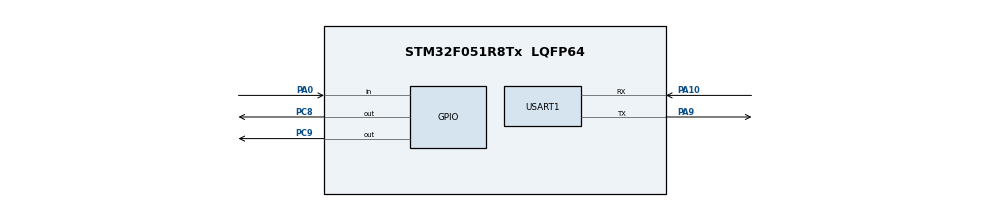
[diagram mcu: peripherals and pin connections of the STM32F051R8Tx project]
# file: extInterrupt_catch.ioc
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Mcu.Family=STM32F0
Mcu.Name=STM32F051R8Tx
Mcu.Package=LQFP64
PA0.GPIO_PuPd=GPIO_PULLUP
PA0.Signal=GPIO_Input
PA10.Mode=Asynchronous
PA10.Signal=USART1_RX
PA9.Mode=Asynchronous
PA9.Signal=USART1_TX
PC8.Signal=GPIO_Output
PC9.Signal=GPIO_Output
ProjectManager.HeapSize=0x200
ProjectManager.StackSize=0x400
ProjectManager.TargetToolchain=MDK-ARM V5.27
RCC.AHBFreq_Value=8000000
RCC.APB1Freq_Value=8000000
RCC.APB1TimFreq_Value=8000000
RCC.HCLKFreq_Value=8000000
USART1.VirtualMode-Asynchronous=VM_ASYNC
board=custom

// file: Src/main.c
/* USER CODE BEGIN Header */
/**
  ******************************************************************************
  * @file           : main.c
  * @brief          : Main program body
  ******************************************************************************
  * @attention
  *
  * <h2><center>&copy; Copyright (c) 2020 STMicroelectronics.
  * All rights reserved.</center></h2>
  *
  * This software component is licensed by ST under BSD 3-Clause license,
  * the "License"; You may not use this file except in compliance with the
  * License. You may obtain a copy of the License at:
  *                        opensource.org/licenses/BSD-3-Clause
  *
  ******************************************************************************
  */
/* USER CODE END Header */

#include "main.h"

UART_HandleTypeDef huart1;

void SystemClock_Config(void);
static void MX_GPIO_Init(void);
static void MX_USART1_UART_Init(void);
static void MX_NVIC_Init(void);
/* USER CODE BEGIN PFP */

void HAL_GPIO_EXTI_Callback(uint16_t GPIO_Pin);
/* USER CODE END PFP */

int main(void)
{

  /* MCU Configuration--------------------------------------------------------*/

  /* Reset of all peripherals, Initializes the Flash interface and the Systick. */
  HAL_Init();

  /* Configure the system clock */
  SystemClock_Config();

  /* Initialize all configured peripherals */
  MX_GPIO_Init();
  MX_USART1_UART_Init();

  /* Initialize interrupts */
  MX_NVIC_Init();
  /* USER CODE BEGIN 2 */
  HAL_UART_Transmit(&huart1, "START\n", 6, 10);

  /* USER CODE END 2 */

  /* Infinite loop */
  while (1)
  {
	  if(HAL_GPIO_ReadPin(GPIOA, GPIO_PIN_0) == 1){
		  HAL_GPIO_WritePin(GPIOC, GPIO_PIN_9,GPIO_PIN_SET);
	  }
	  else{
		  HAL_GPIO_WritePin(GPIOC, GPIO_PIN_9,GPIO_PIN_RESET);
	  }

  }
}

void SystemClock_Config(void)
{
  RCC_OscInitTypeDef RCC_OscInitStruct = {0};
  RCC_ClkInitTypeDef RCC_ClkInitStruct = {0};
  RCC_PeriphCLKInitTypeDef PeriphClkInit = {0};

  /** Initializes the CPU, AHB and APB busses clocks
  */
  RCC_OscInitStruct.OscillatorType = RCC_OSCILLATORTYPE_HSI;
  RCC_OscInitStruct.HSIState = RCC_HSI_ON;
  RCC_OscInitStruct.HSICalibrationValue = RCC_HSICALIBRATION_DEFAULT;
  RCC_OscInitStruct.PLL.PLLState = RCC_PLL_NONE;
  if (HAL_RCC_OscConfig(&RCC_OscInitStruct) != HAL_OK)
  {
    Error_Handler();
  }
  /** Initializes the CPU, AHB and APB busses clocks
  */
  RCC_ClkInitStruct.ClockType = RCC_CLOCKTYPE_HCLK|RCC_CLOCKTYPE_SYSCLK
                              |RCC_CLOCKTYPE_PCLK1;
  RCC_ClkInitStruct.SYSCLKSource = RCC_SYSCLKSOURCE_HSI;
  RCC_ClkInitStruct.AHBCLKDivider = RCC_SYSCLK_DIV1;
  RCC_ClkInitStruct.APB1CLKDivider = RCC_HCLK_DIV1;

  if (HAL_RCC_ClockConfig(&RCC_ClkInitStruct, FLASH_LATENCY_0) != HAL_OK)
  {
    Error_Handler();
  }
  PeriphClkInit.PeriphClockSelection = RCC_PERIPHCLK_USART1;
  PeriphClkInit.Usart1ClockSelection = RCC_USART1CLKSOURCE_PCLK1;
  if (HAL_RCCEx_PeriphCLKConfig(&PeriphClkInit) != HAL_OK)
  {
    Error_Handler();
  }
}

/**
  * @brief NVIC Configuration.
  * @retval None
  */
static void MX_NVIC_Init(void)
{
  /* EXTI0_1_IRQn interrupt configuration */
  HAL_NVIC_SetPriority(EXTI0_1_IRQn, 2, 0);
  HAL_NVIC_EnableIRQ(EXTI0_1_IRQn);

	/*
	Be careful set NVIC Priority (default : 0, changed : 2)

	*/
}

static void MX_USART1_UART_Init(void)
{

  huart1.Instance = USART1;
  huart1.Init.BaudRate = 115200;
  huart1.Init.WordLength = UART_WORDLENGTH_8B;
  huart1.Init.StopBits = UART_STOPBITS_1;
  huart1.Init.Parity = UART_PARITY_NONE;
  huart1.Init.Mode = UART_MODE_TX_RX;
  huart1.Init.HwFlowCtl = UART_HWCONTROL_NONE;
  huart1.Init.OverSampling = UART_OVERSAMPLING_16;
  huart1.Init.OneBitSampling = UART_ONE_BIT_SAMPLE_DISABLE;
  huart1.AdvancedInit.AdvFeatureInit = UART_ADVFEATURE_NO_INIT;
  if (HAL_UART_Init(&huart1) != HAL_OK)
  {
    Error_Handler();
  }

}

static void MX_GPIO_Init(void)
{
  GPIO_InitTypeDef GPIO_InitStruct = {0};

  /* GPIO Ports Clock Enable */
  __HAL_RCC_GPIOC_CLK_ENABLE();
  __HAL_RCC_GPIOA_CLK_ENABLE();

  /*Configure GPIO pin Output Level */
  HAL_GPIO_WritePin(GPIOC, GPIO_PIN_8|GPIO_PIN_9, GPIO_PIN_RESET);

  /*Configure GPIO pin : PC0 */
  GPIO_InitStruct.Pin = GPIO_PIN_0;
  GPIO_InitStruct.Mode = GPIO_MODE_IT_FALLING;
  GPIO_InitStruct.Pull = GPIO_PULLUP;
  HAL_GPIO_Init(GPIOC, &GPIO_InitStruct);

  /*Configure GPIO pin : PA0 */
  GPIO_InitStruct.Pin = GPIO_PIN_0;
  GPIO_InitStruct.Mode = GPIO_MODE_INPUT;
  GPIO_InitStruct.Pull = GPIO_NOPULL;
  HAL_GPIO_Init(GPIOA, &GPIO_InitStruct);

  /*Configure GPIO pins : PC8 PC9 */
  GPIO_InitStruct.Pin = GPIO_PIN_8|GPIO_PIN_9;
  GPIO_InitStruct.Mode = GPIO_MODE_OUTPUT_PP;
  GPIO_InitStruct.Pull = GPIO_NOPULL;
  GPIO_InitStruct.Speed = GPIO_SPEED_FREQ_LOW;
  HAL_GPIO_Init(GPIOC, &GPIO_InitStruct);

}

/* USER CODE BEGIN 4 */

/*
	__weak function copy and paste at stm32_it.c
	and modify this.
*/
void HAL_GPIO_EXTI_Callback(uint16_t GPIO_Pin)
{
	HAL_GPIO_WritePin(GPIOC, GPIO_PIN_9,GPIO_PIN_SET);
	HAL_Delay(1);
}

/* USER CODE END 4 */

void Error_Handler(void)
{
}

/************************ (C) COPYRIGHT STMicroelectronics *****END OF FILE****/
